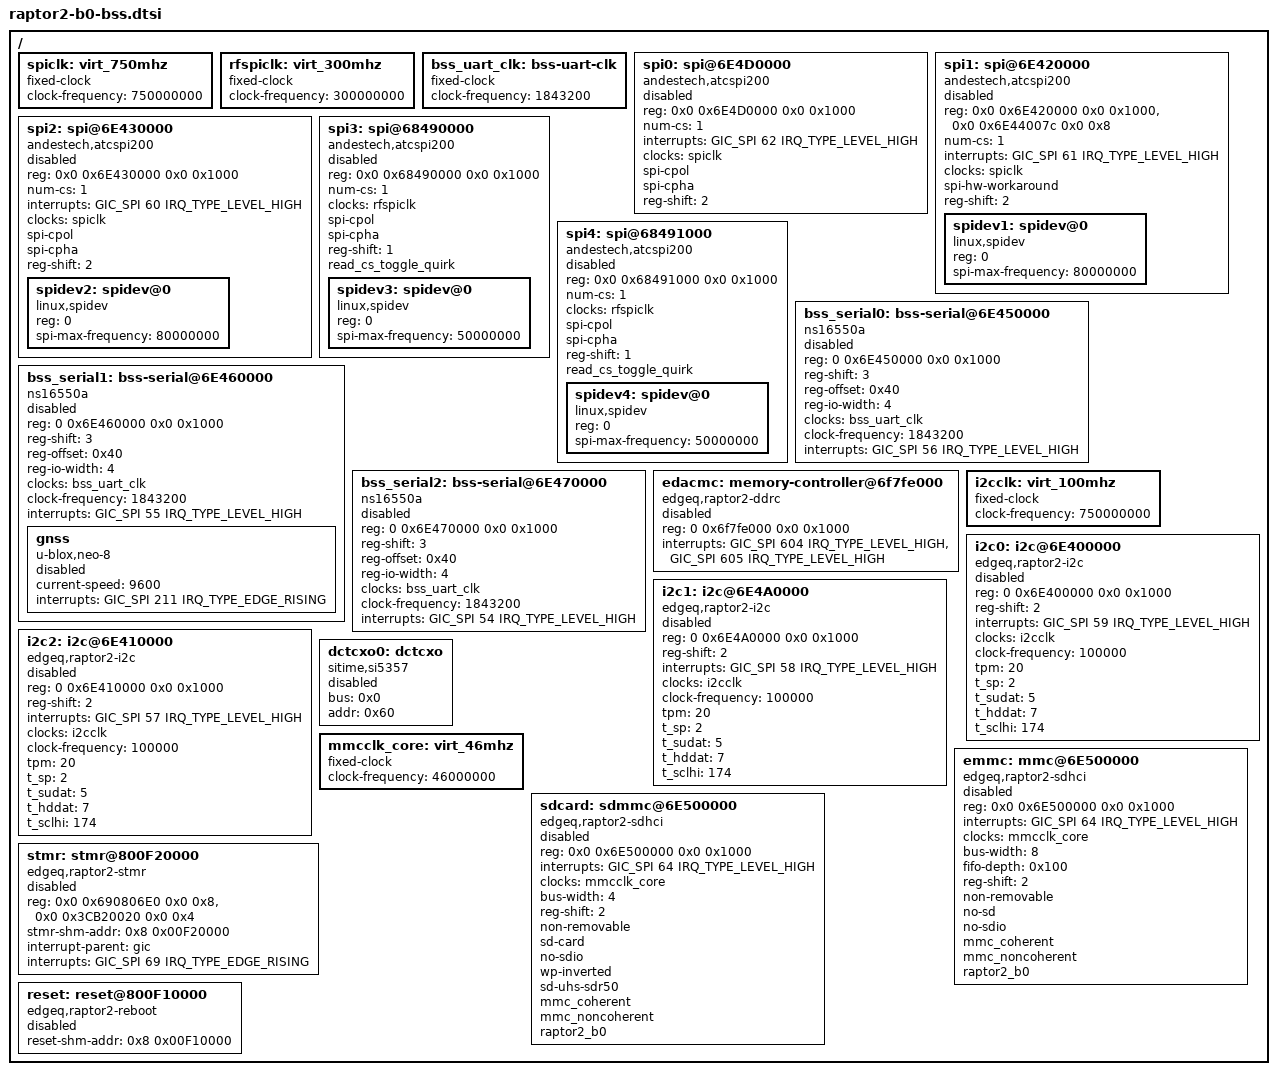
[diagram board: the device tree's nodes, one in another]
// SPDX-License-Identifier: GPL-2.0
/*
 * EdgeQ Inc.
 *
 * EdgeQ Raptor2 BSS DTSi
 */

/ {

	spiclk: virt_750mhz {
		#clock-cells = <0>;
		compatible = "fixed-clock";
		clock-frequency = <750000000>;
	};

	rfspiclk: virt_300mhz {
		#clock-cells = <0>;
		compatible = "fixed-clock";
		clock-frequency = <300000000>;
	};

	bss_uart_clk: bss-uart-clk {
		compatible = "fixed-clock";
		#clock-cells = <0>;
		/*clock-frequency = <9216000>; FPGA */
		clock-frequency = <1843200>; /* Divisor = (1843200 / (19200 * 16)) = 6 */
	};

	spi0: spi@6E4D0000 {
		status = "disabled";
		compatible = "andestech,atcspi200";
		reg = <0x0 0x6E4D0000 0x0 0x1000>;
		num-cs = <1>;
		interrupts = <GIC_SPI 62 IRQ_TYPE_LEVEL_HIGH>;
		clocks = <&spiclk>;
		spi-cpol;
		spi-cpha;
		#address-cells = <1>;
		#size-cells = <0>;
		reg-shift = <2>;

/*
		flash@0 {
			compatible = "jedec,spi-nor";
			spi-max-frequency = <80000000>;
			reg = <0>;
		};
		spidev0: spidev@0 {
			status = "okay";
			compatible = "linux,spidev";
			reg = <0>;
			spi-max-frequency = <80000000>;
		};
*/
	};

	spi1: spi@6E420000 {
		status = "disabled";
		compatible = "andestech,atcspi200";
		reg = <0x0 0x6E420000 0x0 0x1000>,
		      <0x0 0x6E44007c 0x0 0x8>; /* workaround for SPI */
		reg-names = "spi1", "gpio46";
		num-cs = <1>;
		interrupts = <GIC_SPI 61 IRQ_TYPE_LEVEL_HIGH>;
		clocks = <&spiclk>;
		spi-hw-workaround;
		#address-cells = <1>;
		#size-cells = <0>;
		reg-shift = <2>;

		spidev1: spidev@0 {
			status = "okay";
			compatible = "linux,spidev";
			reg = <0>;
			spi-max-frequency = <80000000>;
		};
	};

	spi2: spi@6E430000 {
		status = "disabled";
		compatible = "andestech,atcspi200";
		reg = <0x0 0x6E430000 0x0 0x1000>;
		num-cs = <1>;
		interrupts = <GIC_SPI 60 IRQ_TYPE_LEVEL_HIGH>;
		clocks = <&spiclk>;
		spi-cpol;
		spi-cpha;
		#address-cells = <1>;
		#size-cells = <0>;
		reg-shift = <2>;

		spidev2: spidev@0 {
			status = "okay";
			compatible = "linux,spidev";
			reg = <0>;
			spi-max-frequency = <80000000>;
		};
	};

	spi3: spi@68490000 {
		status = "disabled";
		compatible = "andestech,atcspi200";
		reg = <0x0 0x68490000 0x0 0x1000>;
		num-cs = <1>;
		//interrupts = <GIC_SPI 10 IRQ_TYPE_LEVEL_HIGH>;
		clocks = <&rfspiclk>;
		spi-cpol;
		spi-cpha;
		#address-cells = <1>;
		#size-cells = <0>;
		reg-shift = <1>;
		read_cs_toggle_quirk;

		spidev3: spidev@0 {
			status = "okay";
			compatible = "linux,spidev";
			reg = <0>;
			spi-max-frequency = <50000000>;
		};
	};

	spi4: spi@68491000 {
		status = "disabled";
		compatible = "andestech,atcspi200";
		reg = <0x0 0x68491000 0x0 0x1000>;
		num-cs = <1>;
		//interrupts = <GIC_SPI 10 IRQ_TYPE_LEVEL_HIGH>;
		clocks = <&rfspiclk>;
		spi-cpol;
		spi-cpha;
		#address-cells = <1>;
		#size-cells = <0>;
		reg-shift = <1>;
		read_cs_toggle_quirk;

		spidev4: spidev@0 {
			status = "okay";
			compatible = "linux,spidev";
			reg = <0>;
			spi-max-frequency = <50000000>;
		};
	};

	bss_serial0: bss-serial@6E450000 {
		status = "disabled";
		device_type = "serial";
		compatible = "ns16550a";
		reg = <0 0x6E450000 0x0 0x1000>;
		reg-shift = <3>;
		reg-offset = <0x40>;
                reg-io-width = <4>;
                clocks = <&bss_uart_clk>;
                /*clock-frequency = <9216000>; FPGA */
                clock-frequency = <1843200>;
		interrupts = <GIC_SPI 56 IRQ_TYPE_LEVEL_HIGH>;
	};

	bss_serial1: bss-serial@6E460000 {
		status = "disabled";
		device_type = "serial";
		compatible = "ns16550a";
		reg = <0 0x6E460000 0x0 0x1000>;
		reg-shift = <3>;
		reg-offset = <0x40>;
                reg-io-width = <4>;
                clocks = <&bss_uart_clk>;
                /*clock-frequency = <9216000>; FPGA */
                clock-frequency = <1843200>;
		interrupts = <GIC_SPI 55 IRQ_TYPE_LEVEL_HIGH>;

		gnss {
			status = "disabled";
			compatible = "u-blox,neo-8";
			current-speed = <9600>;
			interrupts = <GIC_SPI 211 IRQ_TYPE_EDGE_RISING>;
		};
	};

	bss_serial2: bss-serial@6E470000 {
		status = "disabled";
		device_type = "serial";
		compatible = "ns16550a";
		reg = <0 0x6E470000 0x0 0x1000>;
		reg-shift = <3>;
		reg-offset = <0x40>;
                reg-io-width = <4>;
                clocks = <&bss_uart_clk>;
                /*clock-frequency = <9216000>; FPGA */
                clock-frequency = <1843200>;
		interrupts = <GIC_SPI 54 IRQ_TYPE_LEVEL_HIGH>;
	};

	edacmc: memory-controller@6f7fe000 {
		status = "disabled";
		compatible = "edgeq,raptor2-ddrc";
		reg = <0 0x6f7fe000 0x0 0x1000>;
		interrupts = <GIC_SPI 604 IRQ_TYPE_LEVEL_HIGH>,
			     <GIC_SPI 605 IRQ_TYPE_LEVEL_HIGH>;
        };

	i2cclk: virt_100mhz {
		#clock-cells = <0>;
		compatible = "fixed-clock";
		clock-frequency = <750000000>;
	};

	i2c0: i2c@6E400000 {
		status = "disabled";
		compatible = "edgeq,raptor2-i2c";
		reg = <0 0x6E400000 0x0 0x1000>;
		reg-shift = <2>;
		interrupts = <GIC_SPI 59 IRQ_TYPE_LEVEL_HIGH>;
		clocks = <&i2cclk>;
		clock-frequency = <100000>;
		#address-cells = <1>;
		#size-cells = <0>;
		tpm = <20>;
		t_sp = <2>;
		t_sudat = <5>;
		t_hddat = <7>;
		t_sclhi = <174>;
	};

	i2c1: i2c@6E4A0000 {
		status = "disabled";
		compatible = "edgeq,raptor2-i2c";
		reg = <0 0x6E4A0000 0x0 0x1000>;
		reg-shift = <2>;
		interrupts = <GIC_SPI 58 IRQ_TYPE_LEVEL_HIGH>;
		clocks = <&i2cclk>;
		clock-frequency = <100000>;
		#address-cells = <1>;
		#size-cells = <0>;
		tpm = <20>;
		t_sp = <2>;
		t_sudat = <5>;
		t_hddat = <7>;
		t_sclhi = <174>;
	};

	i2c2: i2c@6E410000 {
		status = "disabled";
		compatible = "edgeq,raptor2-i2c";
		reg = <0 0x6E410000 0x0 0x1000>;
		reg-shift = <2>;
		interrupts = <GIC_SPI 57 IRQ_TYPE_LEVEL_HIGH>;
		clocks = <&i2cclk>;
		clock-frequency = <100000>;
		#address-cells = <1>;
		#size-cells = <0>;
		tpm = <20>;
		t_sp = <2>;
		t_sudat = <5>;
		t_hddat = <7>;
		t_sclhi = <174>;
	};

	dctcxo0: dctcxo {
		status = "disabled";
		compatible = "sitime,si5357";
		bus = <0x0>;
		addr = <0x60>;
	};

	mmcclk_core: virt_46mhz {
		#clock-cells = <0>;
		compatible = "fixed-clock";
		clock-frequency = <46000000>;
	};

	emmc: mmc@6E500000 {
		status = "disabled";
		compatible = "edgeq,raptor2-sdhci";
		reg = <0x0 0x6E500000 0x0 0x1000>;
		interrupts = <GIC_SPI 64 IRQ_TYPE_LEVEL_HIGH>;
		clocks = <&mmcclk_core>;
		clock-names = "core";
		bus-width = <8>;
		fifo-depth = <0x100>;
		reg-shift = <2>;
		non-removable;
		no-sd;
		no-sdio;
		mmc_coherent;
		mmc_noncoherent;
		raptor2_b0;
	};

	sdcard: sdmmc@6E500000 {
		status = "disabled";
		compatible = "edgeq,raptor2-sdhci";
		reg = <0x0 0x6E500000 0x0 0x1000>;
		interrupts = <GIC_SPI 64 IRQ_TYPE_LEVEL_HIGH>;
		clocks = <&mmcclk_core>;
		clock-names = "core";
		bus-width = <4>;
		reg-shift = <2>;
		non-removable;
		sd-card;
		no-sdio;
		wp-inverted;
		sd-uhs-sdr50;
		mmc_coherent;
		mmc_noncoherent;
		raptor2_b0;
	};

	stmr: stmr@800F20000 {
		status = "disabled";
		compatible = "edgeq,raptor2-stmr";
		reg = <0x0 0x690806E0 0x0 0x8>,	/* SIF reg event 69 */
		      <0x0 0x3CB20020 0x0 0x4>;	/* IOSS mux 0 addr */
		stmr-shm-addr = <0x8 0x00F20000>;
		interrupt-parent = <&gic>;
		interrupts = <GIC_SPI 69 IRQ_TYPE_EDGE_RISING>;
	};

	reset: reset@800F10000 {
		status = "disabled";
		compatible = "edgeq,raptor2-reboot";
		reset-shm-addr = <0x8 0x00F10000>;
	};
};
